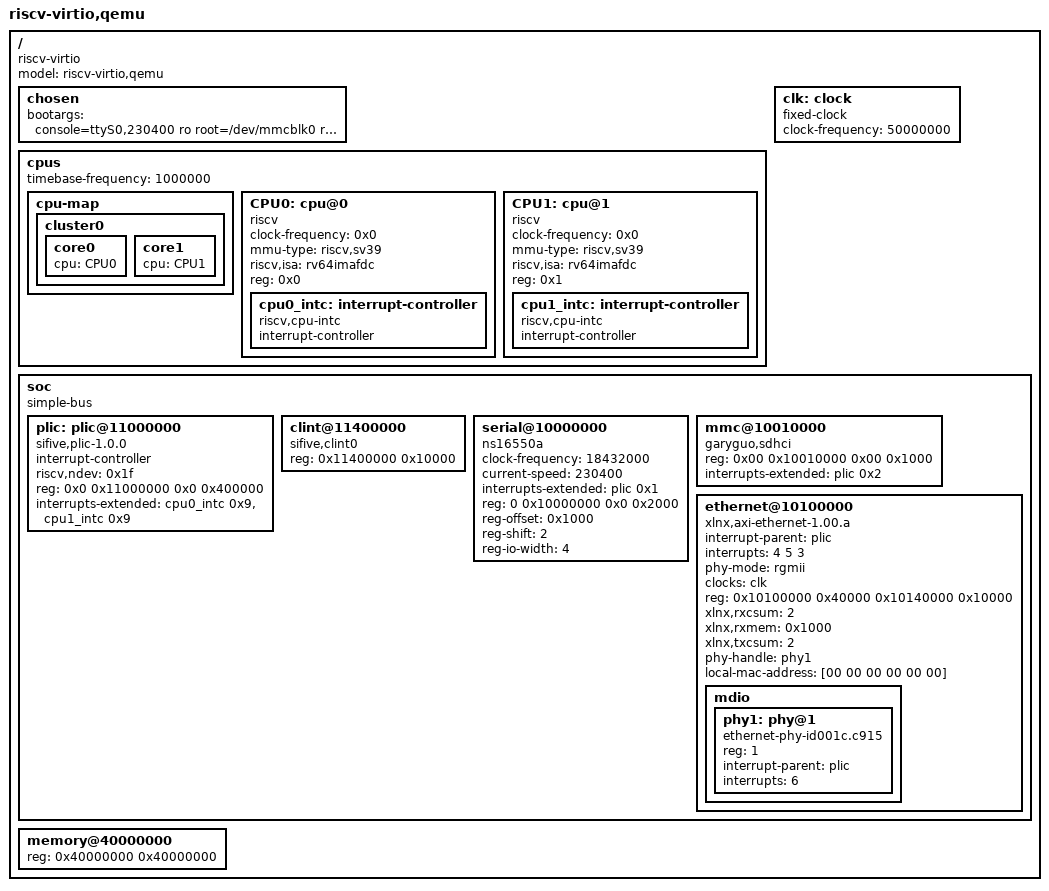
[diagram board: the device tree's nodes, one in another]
/dts-v1/;

/ {
    model = "riscv-virtio,qemu";
    compatible = "riscv-virtio";
    #address-cells = <0x2>;
    #size-cells = <0x2>;

    chosen {
        bootargs = "console=ttyS0,230400 ro root=/dev/mmcblk0 rootflags=noload init=/bin/bash rcupdate.rcu_cpu_stall_suppress=1 rootwait";
    };

    cpus {
        timebase-frequency = <1000000>;
        #address-cells = <0x1>;
        #size-cells = <0x0>;

        cpu-map {
            cluster0 {
                core0 {
                    cpu = <&CPU0>;
                };
                core1 {
                    cpu = <&CPU1>;
                };
            };
        };

        CPU0: cpu@0 {
            clock-frequency = <0x0>;
            mmu-type = "riscv,sv39";
            riscv,isa = "rv64imafdc";
            compatible = "riscv";
            status = "okay";
            reg = <0x0>;
            device_type = "cpu";

            cpu0_intc: interrupt-controller {
                #interrupt-cells = <0x1>;
                interrupt-controller;
                compatible = "riscv,cpu-intc";
            };
        };

        CPU1: cpu@1 {
            clock-frequency = <0x0>;
            mmu-type = "riscv,sv39";
            riscv,isa = "rv64imafdc";
            compatible = "riscv";
            status = "okay";
            reg = <0x1>;
            device_type = "cpu";

            cpu1_intc: interrupt-controller {
                #interrupt-cells = <0x1>;
                interrupt-controller;
                compatible = "riscv,cpu-intc";
            };
        };
    };

    clk: clock {
        compatible = "fixed-clock";
        #clock-cells = <0>;
        clock-frequency = <50000000>;
    };

    soc {
        ranges;
        compatible = "simple-bus";
        #address-cells = <0x2>;
        #size-cells = <0x2>;

        plic: plic@11000000 {
            #interrupt-cells = <0x1>;
            interrupt-controller;
            compatible = "sifive,plic-1.0.0";
            riscv,ndev = <0x1f>;
            reg = <0x0 0x11000000 0x0 0x400000>;
            interrupts-extended = <&cpu0_intc 0x9 &cpu1_intc 0x9>;
        };

        clint@11400000 {
            compatible = "sifive,clint0";
            reg = /bits/ 64 <0x11400000 0x10000>;
        };

        serial@10000000 {
            clock-frequency = <18432000>;
            compatible = "ns16550a";
            current-speed = <230400>;
            interrupts-extended = <&plic 0x1>;
            reg = <0 0x10000000 0x0 0x2000>;
            reg-offset = <0x1000>;
            reg-shift = <2>;
            reg-io-width = <4>;
        };

        mmc@10010000 {
            compatible = "garyguo,sdhci";
            reg = <0x00 0x10010000 0x00 0x1000>;
            interrupts-extended = <&plic 0x2>;
        };

        ethernet@10100000 {
            compatible = "xlnx,axi-ethernet-1.00.a";
            device_type = "network";
            interrupt-parent = <&plic>;
            interrupts = <4 5 3>;
            phy-mode = "rgmii";
            clocks = <&clk>;
            reg = /bits/ 64 <0x10100000 0x40000 0x10140000 0x10000>;
            xlnx,rxcsum = <2>;
            xlnx,rxmem = <0x1000>;
            xlnx,txcsum = <2>;
            phy-handle = <&phy1>;
            local-mac-address = [00 00 00 00 00 00];
            mdio {
                #address-cells = <1>;
                #size-cells = <0>;
                phy1: phy@1 {
                    compatible = "ethernet-phy-id001c.c915";
                    device_type = "ethernet-phy";
                    reg = <1>;
                    interrupt-parent = <&plic>;
                    interrupts = <6>;
                };
            };
        };
    };

    memory@40000000 {
        reg = /bits/ 64 <0x40000000 0x40000000>;
        device_type = "memory";
    };
};
